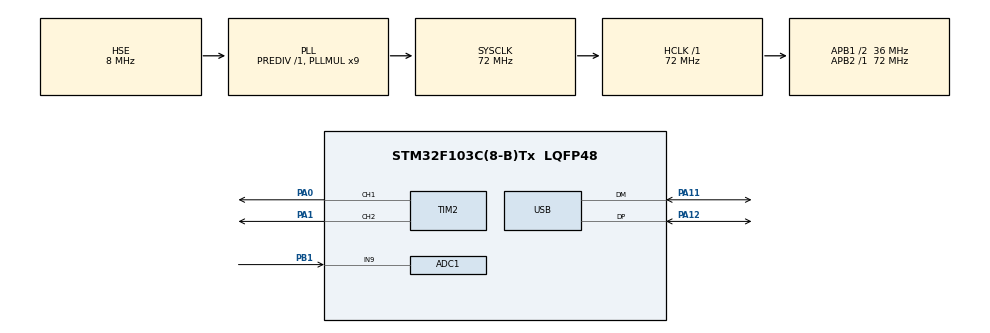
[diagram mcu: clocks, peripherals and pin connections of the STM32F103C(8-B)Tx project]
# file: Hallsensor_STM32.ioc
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ADC1.Channel-4\#ChannelRegularConversion=ADC_CHANNEL_9
ADC1.NbrOfConversionFlag=1
ADC1.Rank-4\#ChannelRegularConversion=1
ADC1.SamplingTime-4\#ChannelRegularConversion=ADC_SAMPLETIME_1CYCLE_5
ADC1.master=1
FREERTOS.Tasks01=defaultTask,0,128,StartDefaultTask,Default,NULL
Mcu.Family=STM32F1
Mcu.Name=STM32F103C(8-B)Tx
Mcu.Package=LQFP48
NVIC.PriorityGroup=NVIC_PRIORITYGROUP_4
NVIC.USB_LP_CAN1_RX0_IRQn=true\:5\:0\:false\:false\:true\:true\:false
PA0-WKUP.Signal=S_TIM2_CH1_ETR
PA1.Signal=S_TIM2_CH2
PA11.Mode=Device
PA11.Signal=USB_DM
PA12.Mode=Device
PA12.Signal=USB_DP
PA13.Mode=Serial_Wire
PA13.Signal=SYS_JTMS-SWDIO
PA14.Mode=Serial_Wire
PA14.Signal=SYS_JTCK-SWCLK
PB1.Signal=ADCx_IN9
PC14-OSC32_IN.Mode=LSE-External-Oscillator
PC14-OSC32_IN.Signal=RCC_OSC32_IN
PC15-OSC32_OUT.Mode=LSE-External-Oscillator
PC15-OSC32_OUT.Signal=RCC_OSC32_OUT
PD0-OSC_IN.Mode=HSE-External-Oscillator
PD0-OSC_IN.Signal=RCC_OSC_IN
PD1-OSC_OUT.Mode=HSE-External-Oscillator
PD1-OSC_OUT.Signal=RCC_OSC_OUT
ProjectManager.HeapSize=0x200
ProjectManager.StackSize=0x400
ProjectManager.TargetToolchain=SW4STM32
RCC.AHBFreq_Value=72000000
RCC.APB1CLKDivider=RCC_HCLK_DIV2
RCC.APB1Freq_Value=36000000
RCC.APB1TimFreq_Value=72000000
RCC.APB2Freq_Value=72000000
RCC.APB2TimFreq_Value=72000000
RCC.HCLKFreq_Value=72000000
RCC.PLLMUL=RCC_PLL_MUL9
RCC.SYSCLKFreq_VALUE=72000000
RCC.SYSCLKSource=RCC_SYSCLKSOURCE_PLLCLK
RCC.USBFreq_Value=48000000
RCC.USBPrescaler=RCC_USBCLKSOURCE_PLL_DIV1_5
SH.ADCx_IN9.0=ADC1_IN9,IN9
SH.S_TIM2_CH1_ETR.0=TIM2_CH1,PWM Generation1 CH1
SH.S_TIM2_CH2.0=TIM2_CH2,PWM Generation2 CH2
TIM2.Channel-PWM\ Generation1\ CH1=TIM_CHANNEL_1
TIM2.Channel-PWM\ Generation2\ CH2=TIM_CHANNEL_2
USB_DEVICE.CLASS_NAME_FS=CDC
USB_DEVICE.VirtualMode=Cdc
USB_DEVICE.VirtualModeFS=Cdc_FS
VP_FREERTOS_VS_ENABLE.Mode=Enabled
VP_TIM2_VS_ClockSourceINT.Mode=Internal
VP_USB_DEVICE_VS_USB_DEVICE_CDC_FS.Mode=CDC_FS
board=Hallsensor_STM32

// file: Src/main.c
/**
  ******************************************************************************
  * @file           : main.c
  * @brief          : Main program body
  ******************************************************************************
  * This notice applies to any and all portions of this file
  * that are not between comment pairs USER CODE BEGIN and
  * USER CODE END. Other portions of this file, whether
  * inserted by the user or by software development tools
  * are owned by their respective copyright owners.
  *
  * Copyright (c) 2018 STMicroelectronics International N.V.
  * All rights reserved.
  *
  * Redistribution and use in source and binary forms, with or without
  * modification, are permitted, provided that the following conditions are met:
  *
  * 1. Redistribution of source code must retain the above copyright notice,
  *    this list of conditions and the following disclaimer.
  * 2. Redistributions in binary form must reproduce the above copyright notice,
  *    this list of conditions and the following disclaimer in the documentation
  *    and/or other materials provided with the distribution.
  * 3. Neither the name of STMicroelectronics nor the names of other
  *    contributors to this software may be used to endorse or promote products
  *    derived from this software without specific written permission.
  * 4. This software, including modifications and/or derivative works of this
  *    software, must execute solely and exclusively on microcontroller or
  *    microprocessor devices manufactured by or for STMicroelectronics.
  * 5. Redistribution and use of this software other than as permitted under
  *    this license is void and will automatically terminate your rights under
  *    this license.
  *
  * THIS SOFTWARE IS PROVIDED BY STMICROELECTRONICS AND CONTRIBUTORS "AS IS"
  * AND ANY EXPRESS, IMPLIED OR STATUTORY WARRANTIES, INCLUDING, BUT NOT
  * LIMITED TO, THE IMPLIED WARRANTIES OF MERCHANTABILITY, FITNESS FOR A
  * PARTICULAR PURPOSE AND NON-INFRINGEMENT OF THIRD PARTY INTELLECTUAL PROPERTY
  * RIGHTS ARE DISCLAIMED TO THE FULLEST EXTENT PERMITTED BY LAW. IN NO EVENT
  * SHALL STMICROELECTRONICS OR CONTRIBUTORS BE LIABLE FOR ANY DIRECT, INDIRECT,
  * INCIDENTAL, SPECIAL, EXEMPLARY, OR CONSEQUENTIAL DAMAGES (INCLUDING, BUT NOT
  * LIMITED TO, PROCUREMENT OF SUBSTITUTE GOODS OR SERVICES; LOSS OF USE, DATA,
  * OR PROFITS; OR BUSINESS INTERRUPTION) HOWEVER CAUSED AND ON ANY THEORY OF
  * LIABILITY, WHETHER IN CONTRACT, STRICT LIABILITY, OR TORT (INCLUDING
  * NEGLIGENCE OR OTHERWISE) ARISING IN ANY WAY OUT OF THE USE OF THIS SOFTWARE,
  * EVEN IF ADVISED OF THE POSSIBILITY OF SUCH DAMAGE.
  *
  ******************************************************************************
  */
#include "main.h"
#include "stm32f1xx_hal.h"
#include "cmsis_os.h"
#include "usb_device.h"

/* USER CODE BEGIN Includes */
#include "appMain.h"
#include "AnalogIN_B1.h"
#include "PWMcontroller.h"
/* USER CODE END Includes */

ADC_HandleTypeDef hadc1;

TIM_HandleTypeDef htim2;

osThreadId defaultTaskHandle;

/* USER CODE BEGIN PV */
/* Private variables ---------------------------------------------------------*/

/* USER CODE END PV */

void SystemClock_Config(void);
static void MX_GPIO_Init(void);
static void MX_ADC1_Init(void);
static void MX_TIM2_Init(void);
void StartDefaultTask(void const * argument);

void HAL_TIM_MspPostInit(TIM_HandleTypeDef *htim);

/* USER CODE BEGIN PFP */
/* Private function prototypes -----------------------------------------------*/

/* USER CODE END PFP */

int main(void)
{

  /* MCU Configuration----------------------------------------------------------*/

  /* Reset of all peripherals, Initializes the Flash interface and the Systick. */
  HAL_Init();

  /* Configure the system clock */
  SystemClock_Config();

  /* Initialize all configured peripherals */
  MX_GPIO_Init();
  MX_ADC1_Init();
  MX_TIM2_Init();
  /* USER CODE BEGIN 2 */
  setADChandler(&hadc1);
  setTmrHandler(&htim2);
  /* USER CODE END 2 */

  /* Create the thread(s) */
  /* definition and creation of defaultTask */
  osThreadDef(defaultTask, StartDefaultTask, osPriorityNormal, 0, 128);
  defaultTaskHandle = osThreadCreate(osThread(defaultTask), NULL);

  /* Start scheduler */
  osKernelStart();

  /* We should never get here as control is now taken by the scheduler */

  /* Infinite loop */
    while (1)
  {

  }

}

void SystemClock_Config(void)
{

  RCC_OscInitTypeDef RCC_OscInitStruct;
  RCC_ClkInitTypeDef RCC_ClkInitStruct;
  RCC_PeriphCLKInitTypeDef PeriphClkInit;

    /**Initializes the CPU, AHB and APB busses clocks
    */
  RCC_OscInitStruct.OscillatorType = RCC_OSCILLATORTYPE_HSE;
  RCC_OscInitStruct.HSEState = RCC_HSE_ON;
  RCC_OscInitStruct.HSEPredivValue = RCC_HSE_PREDIV_DIV1;
  RCC_OscInitStruct.HSIState = RCC_HSI_ON;
  RCC_OscInitStruct.PLL.PLLState = RCC_PLL_ON;
  RCC_OscInitStruct.PLL.PLLSource = RCC_PLLSOURCE_HSE;
  RCC_OscInitStruct.PLL.PLLMUL = RCC_PLL_MUL9;
  if (HAL_RCC_OscConfig(&RCC_OscInitStruct) != HAL_OK)
  {
    _Error_Handler(__FILE__, __LINE__);
  }

    /**Initializes the CPU, AHB and APB busses clocks
    */
  RCC_ClkInitStruct.ClockType = RCC_CLOCKTYPE_HCLK|RCC_CLOCKTYPE_SYSCLK
                              |RCC_CLOCKTYPE_PCLK1|RCC_CLOCKTYPE_PCLK2;
  RCC_ClkInitStruct.SYSCLKSource = RCC_SYSCLKSOURCE_PLLCLK;
  RCC_ClkInitStruct.AHBCLKDivider = RCC_SYSCLK_DIV1;
  RCC_ClkInitStruct.APB1CLKDivider = RCC_HCLK_DIV2;
  RCC_ClkInitStruct.APB2CLKDivider = RCC_HCLK_DIV1;

  if (HAL_RCC_ClockConfig(&RCC_ClkInitStruct, FLASH_LATENCY_2) != HAL_OK)
  {
    _Error_Handler(__FILE__, __LINE__);
  }

  PeriphClkInit.PeriphClockSelection = RCC_PERIPHCLK_ADC|RCC_PERIPHCLK_USB;
  PeriphClkInit.AdcClockSelection = RCC_ADCPCLK2_DIV2;
  PeriphClkInit.UsbClockSelection = RCC_USBCLKSOURCE_PLL_DIV1_5;
  if (HAL_RCCEx_PeriphCLKConfig(&PeriphClkInit) != HAL_OK)
  {
    _Error_Handler(__FILE__, __LINE__);
  }

    /**Configure the Systick interrupt time
    */
  HAL_SYSTICK_Config(HAL_RCC_GetHCLKFreq()/1000);

    /**Configure the Systick
    */
  HAL_SYSTICK_CLKSourceConfig(SYSTICK_CLKSOURCE_HCLK);

  /* SysTick_IRQn interrupt configuration */
  HAL_NVIC_SetPriority(SysTick_IRQn, 15, 0);
}

/* ADC1 init function */
static void MX_ADC1_Init(void)
{

  ADC_ChannelConfTypeDef sConfig;

    /**Common config
    */
  hadc1.Instance = ADC1;
  hadc1.Init.ScanConvMode = ADC_SCAN_DISABLE;
  hadc1.Init.ContinuousConvMode = DISABLE;
  hadc1.Init.DiscontinuousConvMode = DISABLE;
  hadc1.Init.ExternalTrigConv = ADC_SOFTWARE_START;
  hadc1.Init.DataAlign = ADC_DATAALIGN_RIGHT;
  hadc1.Init.NbrOfConversion = 1;
  if (HAL_ADC_Init(&hadc1) != HAL_OK)
  {
    _Error_Handler(__FILE__, __LINE__);
  }

    /**Configure Regular Channel
    */
  sConfig.Channel = ADC_CHANNEL_9;
  sConfig.Rank = ADC_REGULAR_RANK_1;
  sConfig.SamplingTime = ADC_SAMPLETIME_1CYCLE_5;
  if (HAL_ADC_ConfigChannel(&hadc1, &sConfig) != HAL_OK)
  {
    _Error_Handler(__FILE__, __LINE__);
  }

}

/* TIM2 init function */
static void MX_TIM2_Init(void)
{

  TIM_ClockConfigTypeDef sClockSourceConfig;
  TIM_MasterConfigTypeDef sMasterConfig;
  TIM_OC_InitTypeDef sConfigOC;

  htim2.Instance = TIM2;
  htim2.Init.Prescaler = 0;
  htim2.Init.CounterMode = TIM_COUNTERMODE_UP;
  htim2.Init.Period = 0;
  htim2.Init.ClockDivision = TIM_CLOCKDIVISION_DIV1;
  htim2.Init.AutoReloadPreload = TIM_AUTORELOAD_PRELOAD_DISABLE;
  if (HAL_TIM_Base_Init(&htim2) != HAL_OK)
  {
    _Error_Handler(__FILE__, __LINE__);
  }

  sClockSourceConfig.ClockSource = TIM_CLOCKSOURCE_INTERNAL;
  if (HAL_TIM_ConfigClockSource(&htim2, &sClockSourceConfig) != HAL_OK)
  {
    _Error_Handler(__FILE__, __LINE__);
  }

  if (HAL_TIM_PWM_Init(&htim2) != HAL_OK)
  {
    _Error_Handler(__FILE__, __LINE__);
  }

  sMasterConfig.MasterOutputTrigger = TIM_TRGO_RESET;
  sMasterConfig.MasterSlaveMode = TIM_MASTERSLAVEMODE_DISABLE;
  if (HAL_TIMEx_MasterConfigSynchronization(&htim2, &sMasterConfig) != HAL_OK)
  {
    _Error_Handler(__FILE__, __LINE__);
  }

  sConfigOC.OCMode = TIM_OCMODE_PWM1;
  sConfigOC.Pulse = 0;
  sConfigOC.OCPolarity = TIM_OCPOLARITY_HIGH;
  sConfigOC.OCFastMode = TIM_OCFAST_DISABLE;
  if (HAL_TIM_PWM_ConfigChannel(&htim2, &sConfigOC, TIM_CHANNEL_1) != HAL_OK)
  {
    _Error_Handler(__FILE__, __LINE__);
  }

  if (HAL_TIM_PWM_ConfigChannel(&htim2, &sConfigOC, TIM_CHANNEL_2) != HAL_OK)
  {
    _Error_Handler(__FILE__, __LINE__);
  }

  HAL_TIM_MspPostInit(&htim2);

}

/** Configure pins as
        * Analog
        * Input
        * Output
        * EVENT_OUT
        * EXTI
*/
static void MX_GPIO_Init(void)
{

  /* GPIO Ports Clock Enable */
  __HAL_RCC_GPIOC_CLK_ENABLE();
  __HAL_RCC_GPIOD_CLK_ENABLE();
  __HAL_RCC_GPIOA_CLK_ENABLE();
  __HAL_RCC_GPIOB_CLK_ENABLE();

}

/* StartDefaultTask function */
void StartDefaultTask(void const * argument)
{
  /* init code for USB_DEVICE */
  MX_USB_DEVICE_Init();

  /* USER CODE BEGIN 5 */
  /* Infinite loop */
  for(;;)
  {
	appMain();
    osDelay(1);
  }
  /* USER CODE END 5 */
}

void _Error_Handler(char *file, int line)
{
  while(1)
  {
  }
}

/************************ (C) COPYRIGHT STMicroelectronics *****END OF FILE****/
